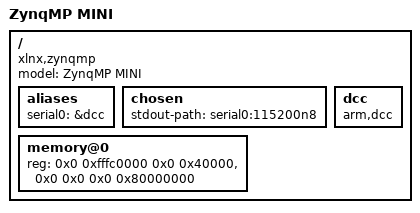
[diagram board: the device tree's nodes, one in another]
// SPDX-License-Identifier: GPL-2.0+
/*
 * dts file for Xilinx ZynqMP Mini Configuration
 *
 * (C) Copyright 2017, Xilinx, Inc.
 *
 * Michal Simek <michal.simek@amd.com>
 */

/dts-v1/;

/ {
	model = "ZynqMP MINI";
	compatible = "xlnx,zynqmp";
	#address-cells = <2>;
	#size-cells = <2>;

	aliases {
		serial0 = &dcc;
	};

	chosen {
		stdout-path = "serial0:115200n8";
	};

	memory@0 {
		device_type = "memory";
		reg = <0x0 0xfffc0000 0x0 0x40000>, <0x0 0x0 0x0 0x80000000>;
	};

	dcc: dcc {
		compatible = "arm,dcc";
		status = "disabled";
		bootph-all;
	};
};

&dcc {
	status = "okay";
};
